AUTOSAR XML (schema 00050)
package /FCADT/ComponentTypes
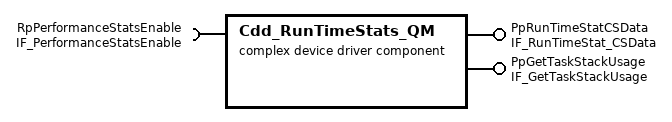
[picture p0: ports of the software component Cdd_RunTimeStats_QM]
  complex device driver sw component type Cdd_RunTimeStats_QM
    require port RpPerformanceStatsEnable: required-interface=IF_PerformanceStatsEnable
      required-com-specs:
        data-element=RunTimeStatsEnable, filter=data-filter-type=ALWAYS, init-value=0
        data-element=StackUsageStatsEnable, filter=data-filter-type=ALWAYS, init-value=0
    provide port PpRunTimeStatCSData: server-com-spec{operation=Cdd_RunTimeStatQM_GetData, queue-length=1}, provided-interface=IF_RunTimeStat_CSData
    provide port PpGetTaskStackUsage: server-com-spec{operation=Data, queue-length=1}, provided-interface=IF_GetTaskStackUsage
    behavior Cdd_RunTimeStats_QM_InternalBehavior
      14 x timing event:
        TMT_Cdd_RunTimeStats_QM_ComTask_10ms_Stop: start-on-event=Cdd_RunTimeStats_QM_ComTask_10ms_Stop, period=0.01
        TMT_Cdd_RunTimeStats_QM_ComTask_10ms_Stop_1: start-on-event=Cdd_RunTimeStats_QM_ComTask_10ms_Start, period=0.01
        TMT_Cdd_RunTimeStats_QM_ComTask_10ms_Stop_2: start-on-event=Cdd_RunTimeStats_QM_ComTask_5ms_Start, period=0.005
        TMT_Cdd_RunTimeStats_QM_ComTask_10ms_Stop_4: start-on-event=Cdd_RunTimeStats_QM_DiagTask_10ms_Start, period=0.01
        TMT_Cdd_RunTimeStats_QM_ComTask_10ms_Stop_5: start-on-event=Cdd_RunTimeStats_QM_DiagTask_10ms_Stop, period=0.01
        TMT_Cdd_RunTimeStats_QM_ComTask_10ms_Stop_6: start-on-event=Cdd_RunTimeStats_QM_MemTask_10ms_Start, period=0.01
        TMT_Cdd_RunTimeStats_QM_ComTask_10ms_Stop_7: start-on-event=Cdd_RunTimeStats_QM_MemTask_10ms_Stop, period=0.01
        TMT_1_Cdd_RunTimeStats_QM_ComTask_5ms_Stop: start-on-event=Cdd_RunTimeStats_QM_ComTask_5ms_Stop, period=0.005
        TMT_Cdd_RunTimeStats_QM_ComTask_10ms_Stop_8: start-on-event=Cdd_RunTimeStats_QM_Task_00_10ms_Start, period=0.01
        TMT_Cdd_RunTimeStats_QM_ComTask_10ms_Stop_9: start-on-event=Cdd_RunTimeStats_QM_Task_00_10ms_Stop, period=0.01
        TMT_Cdd_RunTimeStats_QM_ComTask_10ms_Stop_10: start-on-event=Cdd_RunTimeStats_QM_Task_01_10ms_Start, period=0.01
        TMT_Cdd_RunTimeStats_QM_ComTask_10ms_Stop_11: start-on-event=Cdd_RunTimeStats_QM_Task_01_10ms_Stop, period=0.01
        TMT_Cdd_RunTimeStats_QM_ComTask_10ms_Stop_12: start-on-event=Cdd_RunTimeStats_QM_Task_200ms_Start, period=0.2
        TMT_Cdd_RunTimeStats_QM_ComTask_10ms_Stop_13: start-on-event=Cdd_RunTimeStats_QM_Task_200ms_Stop, period=0.2
      init event Cdd_RunTimeStats_QM_Task_Init_Start_InitEvent: start-on-event=Cdd_RunTimeStats_QM_Task_Init_Start
      init event Cdd_RunTimeStats_QM_Task_Init_Stop_InitEvent: start-on-event=Cdd_RunTimeStats_QM_Task_Init_Stop
      operation invoked event OIT_RE_PpRunTimeStatCSData_Cdd_RunTimeStatQM_GetData_PpRunTimeStatCSData_Cdd_RunTimeStatQM_GetData: start-on-event=RE_PpRunTimeStatCSData_GetData, operation=PpRunTimeStatCSData.Cdd_RunTimeStatQM_GetData
      operation invoked event OIT_PpGetTaskStackUsage_Data_PpGetTaskStackUsage_Data: start-on-event=RE_GetTaskStackUsage_Data, operation=PpGetTaskStackUsage.Data
      18 x runnable:
        Cdd_RunTimeStats_QM_ComTask_10ms_Stop
        Cdd_RunTimeStats_QM_ComTask_10ms_Start
        Cdd_RunTimeStats_QM_ComTask_5ms_Start
        Cdd_RunTimeStats_QM_ComTask_5ms_Stop
        Cdd_RunTimeStats_QM_DiagTask_10ms_Start
        Cdd_RunTimeStats_QM_DiagTask_10ms_Stop
        Cdd_RunTimeStats_QM_MemTask_10ms_Start
        Cdd_RunTimeStats_QM_MemTask_10ms_Stop
        Cdd_RunTimeStats_QM_Task_00_10ms_Start
        Cdd_RunTimeStats_QM_Task_00_10ms_Stop
        Cdd_RunTimeStats_QM_Task_01_10ms_Start
        Cdd_RunTimeStats_QM_Task_01_10ms_Stop
        Cdd_RunTimeStats_QM_Task_200ms_Start
        Cdd_RunTimeStats_QM_Task_200ms_Stop
        Cdd_RunTimeStats_QM_Task_Init_Start
        Cdd_RunTimeStats_QM_Task_Init_Stop
        RE_PpRunTimeStatCSData_GetData
          data-receive-point-by-arguments:
            access REC_RpPerformanceStatsEnable_RunTimeStatsEnable: accessed-variable=RpPerformanceStatsEnable.RunTimeStatsEnable
        RE_GetTaskStackUsage_Data
          data-receive-point-by-arguments:
            access REC_RpPerformanceStatsEnable_StackUsageStatsEnable: accessed-variable=RpPerformanceStatsEnable.StackUsageStatsEnable
  swc implementation Cdd_RunTimeStats_QM_Implementation: behavior=Cdd_RunTimeStats_QM_InternalBehavior
